# RL6678_IP_SVD register map
Vendor: Realtek
Registers are 32-bit, read-write, reset 0x0 unless marked. A register's access mark holds for its fields unless they carry their own. Offsets are from the block's base; [hi:lo] are bit positions; {n}, {i} and the like mark numbered series.

## OTPC_REG
Base 0x42000000
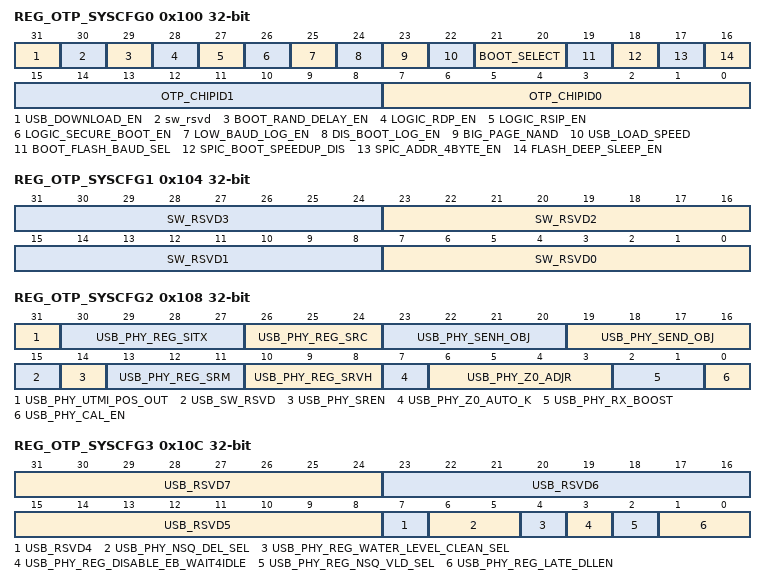
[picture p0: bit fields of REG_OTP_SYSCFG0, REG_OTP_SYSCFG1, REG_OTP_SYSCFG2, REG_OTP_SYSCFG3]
0x100 REG_OTP_SYSCFG0
  [31] USB_DOWNLOAD_EN — USB download enable 0: disable 1: enable
  [30] sw_rsvd
  [29] BOOT_RAND_DELAY_EN — Enable random boot delay 0: disable 1: enable
  [28] LOGIC_RDP_EN — RDP enable
  [27] LOGIC_RSIP_EN — RSIP enable
  [26] LOGIC_SECURE_BOOT_EN — Secure boot enable
  [25] LOW_BAUD_LOG_EN — Loguart Baudrate selection 1: 115200bps 0: 1.5Mbps
  [24] DIS_BOOT_LOG_EN — Boot log disable
  [23] BIG_PAGE_NAND — Nand Flash page 0: 2K 1: 4K
  [22] USB_LOAD_SPEED — USB load speed 1: Full speed 0: High speed
  [21:20] BOOT_SELECT — Boot selection. Boot from Nor Flash, or Nand Flash, or try. 0'b11: Boot option determined by power-on latch 0'b10: Boot from Nor flash 0'b01: Boot from Nand flash 0'b00: Boot option determined by power-on latch
  [19] BOOT_FLASH_BAUD_SEL — Boot Flash clock selection. Baudrate = 40/(2*(1+x)) 0: 20M 1: 10M
  [18] SPIC_BOOT_SPEEDUP_DIS — SPIC boot speed up disable
  [17] SPIC_ADDR_4BYTE_EN — SPIC address 4-byte enable
  [16] FLASH_DEEP_SLEEP_EN — Flash deepsleep enable
  [15:8] OTP_CHIPID1 — OTP autuload data reserved for SW
  [7:0] OTP_CHIPID0 — OTP autuload data reserved for SW
0x104 REG_OTP_SYSCFG1
  [8n+7:8n] SW_RSVD{n} (n=0..3) — RSVD for SW usage
0x108 REG_OTP_SYSCFG2
  [31] USB_PHY_UTMI_POS_OUT — All output signals on UTMI interface are triggered at positive edge of UTMI clock
  [30:27] USB_PHY_REG_SITX — Control magnitude of HSTX output swing IBX_TX = 3.125*sitx+125 (uA) Default : 3.125*8+125 = 150 (uA) IBXDP/IBXDM = 120*IBX_TX Default : 120*0.15 (mA) = 18 (mA) HSDP/HSDM = 18(mA)*45 (Ω) /2 = 405 mV sitx (4-bit): REG_SITX[3:0] IBX_TX(uA): current for HSTX output swing control IBXDP/IBXDM : HSTX DP (or DM) output current HSDP/HSDM : HSTX DP (or DM) output voltage
  [26:24] USB_PHY_REG_SRC — USB PHY slew-rate (rise time ,tr /fall time ,tf) control of HSDP,HSDM, tr: 000: 560ps , 001: 530ps 010: 500ps , 011: 470ps 100: 440ps , 101: 420ps 110: 390ps , 111: 370ps
  [23:20] USB_PHY_SENH_OBJ — USB PHY host squelch level calibration target
  [19:16] USB_PHY_SEND_OBJ — USB PHY device squelch level calibration target
  [15] USB_SW_RSVD
  [14] USB_PHY_SREN — Enable USB PHY new slew rate control for HSTX 0: disable 1: enable
  [13:11] USB_PHY_REG_SRM — USB PHY new slew-rate (rise time ,tr /fall time ,tf) control of HSTX
  [10:8] USB_PHY_REG_SRVH — USB PHY high voltage level of control signal of new slew rate control for HSTX
  [7] USB_PHY_Z0_AUTO_K — USB PHY Zo auto calibration mode 0: Manual mode, Zo value is from REG_Z0_ADJR 1: Auto mode, Zo value is from Zo_Tune
  [6:3] USB_PHY_Z0_ADJR — USB PHY Zo value of manual mode
  [2:1] USB_PHY_RX_BOOST — USB PHY AC boost gain of HSRX amp 00: 0dB 01: 3.3dB 10: 6.9dB 11: 9.3dB
  [0] USB_PHY_CAL_EN — USB PHY calibration enable
0x10C REG_OTP_SYSCFG3
  [31:24] USB_RSVD7 — HW para for USB usage
  [23:16] USB_RSVD6 — HW para for USB usage
  [15:8] USB_RSVD5 — HW para for USB usage
  [7] USB_RSVD4 — HW para for USB usage
  [6:5] USB_PHY_NSQ_DEL_SEL — Modify to RX packet min packet delay 32 bit times. Need delay more than 8 stages in 32 bit times condition. 00:delay 6 stages 01:delay 9 stages 10:delay 11 stages 11:delay 13 stages
  [4] USB_PHY_REG_WATER_LEVEL_CLEAN_SEL — Modify to RX packet min packet delay 32 bit times. Need set 0 in 32 bit times condition. water_level_clean condition: 1'b1: [(start_receive)| (|curr_case)] (old_mode) 1'b0: [(|curr_case)] (new_mode)
  [3] USB_PHY_REG_DISABLE_EB_WAIT4IDLE — Modify to RX packet min packet delay 32 bit times. If first RX packet is too long and water level is too big, need disable EB wait4idle. 1'b0:enable EB wait4idle 1'b1:disable EB wait4idle
  [2] USB_PHY_REG_NSQ_VLD_SEL — Modify to RX packet min packet delay 32 bit times. 1'b1:(NSQ_d[9:0])|NSQ_s (old mode) 1'b0:(NSQ_d[5:0])|NSQ_s (new mode)
  [1:0] USB_PHY_REG_LATE_DLLEN — Modify to TX2RX packet min packet delay 8 bit times. Need less than 7T in 8 bit times condition. HSDLLEN will be asserted to start RX 100ns after TX is done if LATE_DLLEN is set. Else if LATE_DLLEN is cleared, only 66ns duration will be set. This is used to avoid the reception of ECHO following the TX issued by PHY itself. 2'B00:3T 2'B01:5T 2'B10:7T 2'B11:11T
{0x200+4i} REG_KEY_S_IPSEC1_{i} ro reset 0xFFFFFFFF (i=0..7)
  [31:0] key_S_IPSEC1_{i}
{0x220+4i} REG_KEY_S_IPSEC2_{i} ro reset 0xFFFFFFFF (i=0..7)
  [31:0] key_S_IPSEC2_{i}
{0x240+4i} REG_KEY_NS_IPSEC1_{i} ro reset 0xFFFFFFFF (i=0..7)
  [31:0] key_NS_IPSEC1_{i}
{0x260+4i} REG_KEY_NS_IPSEC2_{i} ro reset 0xFFFFFFFF (i=0..7)
  [31:0] key_NS_IPSEC2_{i}
{0x280+4i} REG_KEY_ECDSA_PRI1_{i} ro reset 0xFFFFFFFF (i=0..7)
  [31:0] key_ECDSA_PRI1_{i}
{0x2A0+4i} REG_KEY_ECDSA_PRI2_{i} ro reset 0xFFFFFFFF (i=0..7)
  [31:0] key_ECDSA_PRI2_{i}
{0x2C0+4i} REG_KEY_RSIP_ECB_{i} ro reset 0xFFFFFFFF (i=0..7)
  [31:0] key_RSIP_ECB_{i}
{0x2E0+4i} REG_KEY_RSIP_CTR_{i} ro reset 0xFFFFFFFF (i=0..7)
  [31:0] key_RSIP_CTR_{i}
{0x300+4i} REG_KEY_SWD_PWD_{i} ro reset 0xFFFFFFFF (i=0..3)
  [31:0] key_SWD_PWD_{i}
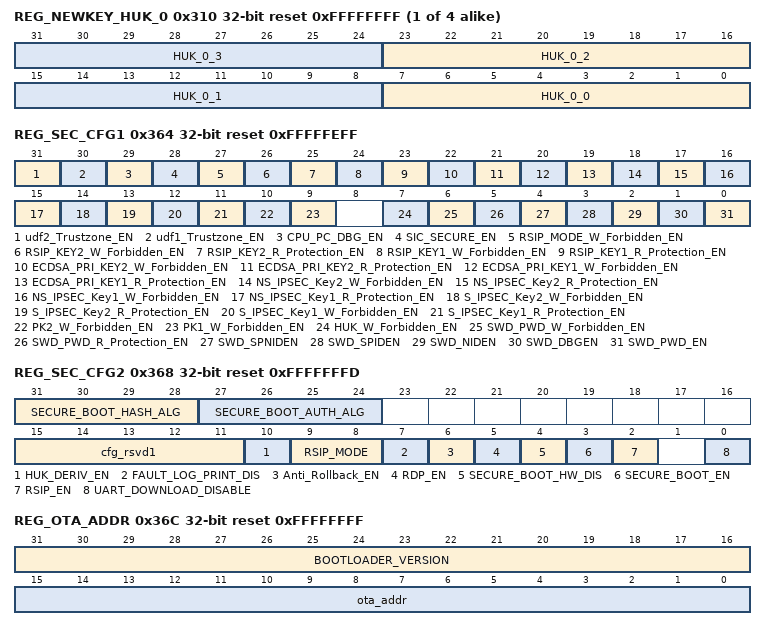
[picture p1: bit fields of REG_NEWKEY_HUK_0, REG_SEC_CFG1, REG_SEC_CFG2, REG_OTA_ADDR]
{0x310+4i} REG_NEWKEY_HUK_{i} ro reset 0xFFFFFFFF (i=0..3)
  [8n+7:8n] HUK_{i}_{n} (n=0..3)
{0x320+4i} REG_PKKEY_PK1_{i} ro reset 0xFFFFFFFF (i=0..7)
  [31:0] key_PK1_{i}
{0x340+4i} REG_PKKEY_PK2_{i} ro reset 0xFFFFFFFF (i=0..7)
  [31:0] key_PK2_{i}
0x360 REG_SEC_CFG0 ro reset 0xFFFFFFFF
  [31:0] swd_id
0x364 REG_SEC_CFG1 ro reset 0xFFFFFEFF
  [31] udf2_Trustzone_EN, [30] udf1_Trustzone_EN, [29] CPU_PC_DBG_EN, [28] SIC_SECURE_EN, [27] RSIP_MODE_W_Forbidden_EN, [26] RSIP_KEY2_W_Forbidden_EN, [25] RSIP_KEY2_R_Protection_EN, [24] RSIP_KEY1_W_Forbidden_EN, [23] RSIP_KEY1_R_Protection_EN, [22] ECDSA_PRI_KEY2_W_Forbidden_EN, [21] ECDSA_PRI_KEY2_R_Protection_EN, [20] ECDSA_PRI_KEY1_W_Forbidden_EN, [19] ECDSA_PRI_KEY1_R_Protection_EN, [18] NS_IPSEC_Key2_W_Forbidden_EN, [17] NS_IPSEC_Key2_R_Protection_EN, [16] NS_IPSEC_Key1_W_Forbidden_EN, [15] NS_IPSEC_Key1_R_Protection_EN, [14] S_IPSEC_Key2_W_Forbidden_EN, [13] S_IPSEC_Key2_R_Protection_EN, [12] S_IPSEC_Key1_W_Forbidden_EN, [11] S_IPSEC_Key1_R_Protection_EN, [10] PK2_W_Forbidden_EN, [9] PK1_W_Forbidden_EN, [7] HUK_W_Forbidden_EN, [6] SWD_PWD_W_Forbidden_EN, [5] SWD_PWD_R_Protection_EN, [4] SWD_SPNIDEN, [3] SWD_SPIDEN, [2] SWD_NIDEN, [1] SWD_DBGEN, [0] SWD_PWD_EN
0x368 REG_SEC_CFG2 ro reset 0xFFFFFFFD
  [31:28] SECURE_BOOT_HASH_ALG, [27:24] SECURE_BOOT_AUTH_ALG, [15:11] cfg_rsvd1, [10] HUK_DERIV_EN, [9:8] RSIP_MODE, [7] FAULT_LOG_PRINT_DIS, [6] Anti_Rollback_EN, [5] RDP_EN, [4] SECURE_BOOT_HW_DIS, [3] SECURE_BOOT_EN, [2] RSIP_EN, [0] UART_DOWNLOAD_DISABLE
0x36C REG_OTA_ADDR ro reset 0xFFFFFFFF
  [31:16] BOOTLOADER_VERSION, [15:0] ota_addr
0x370 REG_CRC0 ro reset 0xFFFFFFFF
  [31:0] crc_entry0 — [15:0] : magic data [31:16]: valid crc Note : this field will be autoload twice time, and stick to L
{0x370+4i} REG_CRC{i} ro reset 0xFFFFFFFF (i=1..3)
  [31:0] crc_entry{i}
0x700 REG_RMA 8-bit ro reset 0xFF
  [7:0] RMA_DATA — If the number of 1 is odd, it will goto RMA state.
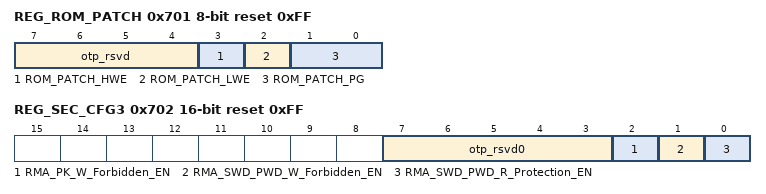
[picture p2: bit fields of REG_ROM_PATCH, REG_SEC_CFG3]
0x701 REG_ROM_PATCH 8-bit ro reset 0xFF
  [7:4] otp_rsvd — RSVD for further use
  [3] ROM_PATCH_HWE — ROM patch write protection (protect High 2Kbits)
  [2] ROM_PATCH_LWE — ROM patch write protection (protect Low 2Kbits)
  [1:0] ROM_PATCH_PG — ROM patch enable.This Bit will programed by FT if ROM patch do not needed
0x702 REG_SEC_CFG3 16-bit ro reset 0xFF
  [7:3] otp_rsvd0, [2] RMA_PK_W_Forbidden_EN, [1] RMA_SWD_PWD_W_Forbidden_EN, [0] RMA_SWD_PWD_R_Protection_EN
{0x710+4i} REG_SWD_RMA_PWD_{i} ro reset 0xFFFFFFFF (i=0..3)
  [31:0] key_RMA_PWD_{i}
{0x720+4i} REG_PKKEY_RMA_PK_{i} ro reset 0xFFFFFFFF (i=0..7)
  [31:0] key_RMA_PK_{i}
